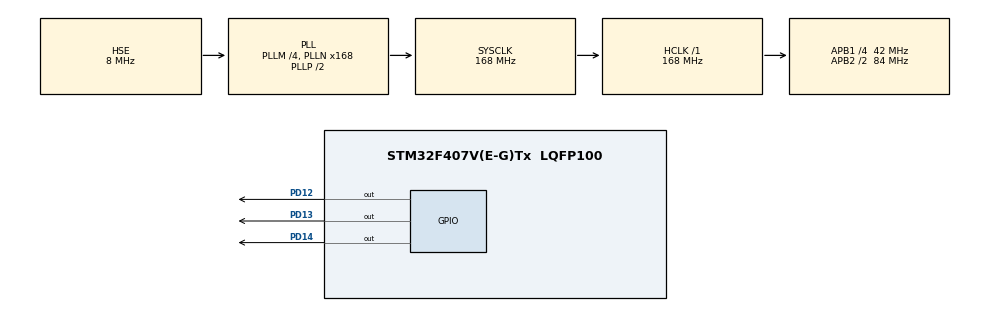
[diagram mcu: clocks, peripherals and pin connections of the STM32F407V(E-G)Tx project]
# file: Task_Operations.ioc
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FREERTOS.BinarySemaphores01=binSema
FREERTOS.INCLUDE_vTaskDelayUntil=1
FREERTOS.Tasks01=myTask01,2,128,init_task_01,Default;myTask02,1,128,init_task_02,Default;myTask03,0,128,init_task_03,Default
Mcu.Family=STM32F4
Mcu.Name=STM32F407V(E-G)Tx
Mcu.Package=LQFP100
NVIC.PriorityGroup=NVIC_PRIORITYGROUP_4
NVIC.TIM1_UP_TIM10_IRQn=true\:0\:0\:false\:false\:true
NVIC.TimeBase=TIM1_UP_TIM10_IRQn
NVIC.TimeBaseIP=TIM1
PA13.Mode=Serial-Wire
PA13.Signal=SYS_JTMS-SWDIO
PA14.Mode=Serial-Wire
PA14.Signal=SYS_JTCK-SWCLK
PD12.GPIO_ModeDefaultOutputPP=GPIO_MODE_OUTPUT_PP
PD12.GPIO_PuPd=GPIO_NOPULL
PD12.GPIO_Speed=GPIO_SPEED_FREQ_VERY_HIGH
PD12.PinState=GPIO_PIN_SET
PD12.Signal=GPIO_Output
PD13.GPIO_ModeDefaultOutputPP=GPIO_MODE_OUTPUT_PP
PD13.GPIO_PuPd=GPIO_NOPULL
PD13.GPIO_Speed=GPIO_SPEED_FREQ_VERY_HIGH
PD13.PinState=GPIO_PIN_SET
PD13.Signal=GPIO_Output
PD14.GPIO_ModeDefaultOutputPP=GPIO_MODE_OUTPUT_PP
PD14.GPIO_PuPd=GPIO_NOPULL
PD14.GPIO_Speed=GPIO_SPEED_FREQ_VERY_HIGH
PD14.PinState=GPIO_PIN_SET
PD14.Signal=GPIO_Output
PH0-OSC_IN.Mode=HSE-External-Oscillator
PH0-OSC_IN.Signal=RCC_OSC_IN
PH1-OSC_OUT.Mode=HSE-External-Oscillator
PH1-OSC_OUT.Signal=RCC_OSC_OUT
ProjectManager.HeapSize=0x600
ProjectManager.StackSize=0x400
ProjectManager.TargetToolchain=MDK-ARM V5
RCC.48MHZClocksFreq_Value=84000000
RCC.AHBFreq_Value=168000000
RCC.APB1CLKDivider=RCC_HCLK_DIV4
RCC.APB1Freq_Value=42000000
RCC.APB1TimCLKDivider=1
RCC.APB1TimFreq_Value=42000000
RCC.APB2CLKDivider=RCC_HCLK_DIV2
RCC.APB2Freq_Value=84000000
RCC.APB2TimCLKDivider=1
RCC.APB2TimFreq_Value=84000000
RCC.CortexFreq_Value=168000000
RCC.HCLKFreq_Value=168000000
RCC.HSE_VALUE=8000000
RCC.HSI_VALUE=16000000
RCC.LSE_VALUE=32768
RCC.PLLM=4
RCC.PLLN=168
RCC.PLLSourceVirtual=RCC_PLLSOURCE_HSE
RCC.SYSCLKFreq_VALUE=168000000
RCC.SYSCLKSource=RCC_SYSCLKSOURCE_PLLCLK
RCC.VCOOutputFreq_Value=336000000
VP_FREERTOS_VS_ENABLE.Mode=Enabled
VP_SYS_VS_tim1.Mode=TIM1
board=Task_Operations

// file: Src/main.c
/**
  ******************************************************************************
  * File Name          : main.c
  * Description        : Main program body
  ******************************************************************************
  *
  * COPYRIGHT(c) 2021 STMicroelectronics
  *
  * Redistribution and use in source and binary forms, with or without modification,
  * are permitted provided that the following conditions are met:
  *   1. Redistributions of source code must retain the above copyright notice,
  *      this list of conditions and the following disclaimer.
  *   2. Redistributions in binary form must reproduce the above copyright notice,
  *      this list of conditions and the following disclaimer in the documentation
  *      and/or other materials provided with the distribution.
  *   3. Neither the name of STMicroelectronics nor the names of its contributors
  *      may be used to endorse or promote products derived from this software
  *      without specific prior written permission.
  *
  * THIS SOFTWARE IS PROVIDED BY THE COPYRIGHT HOLDERS AND CONTRIBUTORS "AS IS"
  * AND ANY EXPRESS OR IMPLIED WARRANTIES, INCLUDING, BUT NOT LIMITED TO, THE
  * IMPLIED WARRANTIES OF MERCHANTABILITY AND FITNESS FOR A PARTICULAR PURPOSE ARE
  * DISCLAIMED. IN NO EVENT SHALL THE COPYRIGHT HOLDER OR CONTRIBUTORS BE LIABLE
  * FOR ANY DIRECT, INDIRECT, INCIDENTAL, SPECIAL, EXEMPLARY, OR CONSEQUENTIAL
  * DAMAGES (INCLUDING, BUT NOT LIMITED TO, PROCUREMENT OF SUBSTITUTE GOODS OR
  * SERVICES; LOSS OF USE, DATA, OR PROFITS; OR BUSINESS INTERRUPTION) HOWEVER
  * CAUSED AND ON ANY THEORY OF LIABILITY, WHETHER IN CONTRACT, STRICT LIABILITY,
  * OR TORT (INCLUDING NEGLIGENCE OR OTHERWISE) ARISING IN ANY WAY OUT OF THE USE
  * OF THIS SOFTWARE, EVEN IF ADVISED OF THE POSSIBILITY OF SUCH DAMAGE.
  *
  ******************************************************************************
  */
#include "stm32f4xx_hal.h"
#include "cmsis_os.h"

osThreadId myTask01Handle;
osThreadId myTask02Handle;
osThreadId myTask03Handle;
osSemaphoreId binSemaHandle;

/* USER CODE BEGIN PV */
/* Private variables ---------------------------------------------------------*/

/* USER CODE END PV */

void SystemClock_Config(void);
static void MX_GPIO_Init(void);
void init_task_01(void const * argument);
void init_task_02(void const * argument);
void init_task_03(void const * argument);

/* USER CODE BEGIN PFP */
/* Private function prototypes -----------------------------------------------*/

/* USER CODE END PFP */

int main(void)
{

  /* MCU Configuration----------------------------------------------------------*/

  /* Reset of all peripherals, Initializes the Flash interface and the Systick. */
  HAL_Init();

  /* Configure the system clock */
  SystemClock_Config();

  /* Initialize all configured peripherals */
  MX_GPIO_Init();

  /* Create the semaphores(s) */
  /* definition and creation of binSema */
  osSemaphoreDef(binSema);
  binSemaHandle = osSemaphoreCreate(osSemaphore(binSema), 1);

  /* Create the thread(s) */
  /* definition and creation of myTask01 */
  osThreadDef(myTask01, init_task_01, osPriorityHigh, 0, 128);
  myTask01Handle = osThreadCreate(osThread(myTask01), NULL);

  /* definition and creation of myTask02 */
  osThreadDef(myTask02, init_task_02, osPriorityAboveNormal, 0, 128);
  myTask02Handle = osThreadCreate(osThread(myTask02), NULL);

  /* definition and creation of myTask03 */
  osThreadDef(myTask03, init_task_03, osPriorityNormal, 0, 128);
  myTask03Handle = osThreadCreate(osThread(myTask03), NULL);

  /* USER CODE BEGIN RTOS_QUEUES */
  /* add queues, ... */
	printf("START\n");
  /* USER CODE END RTOS_QUEUES */

  /* Start scheduler */
  osKernelStart();

  /* We should never get here as control is now taken by the scheduler */

  /* Infinite loop */
  while (1)
  {

  }

}

/** System Clock Configuration
*/
void SystemClock_Config(void)
{

  RCC_OscInitTypeDef RCC_OscInitStruct;
  RCC_ClkInitTypeDef RCC_ClkInitStruct;

  __HAL_RCC_PWR_CLK_ENABLE();

  __HAL_PWR_VOLTAGESCALING_CONFIG(PWR_REGULATOR_VOLTAGE_SCALE1);

  RCC_OscInitStruct.OscillatorType = RCC_OSCILLATORTYPE_HSE;
  RCC_OscInitStruct.HSEState = RCC_HSE_ON;
  RCC_OscInitStruct.PLL.PLLState = RCC_PLL_ON;
  RCC_OscInitStruct.PLL.PLLSource = RCC_PLLSOURCE_HSE;
  RCC_OscInitStruct.PLL.PLLM = 4;
  RCC_OscInitStruct.PLL.PLLN = 168;
  RCC_OscInitStruct.PLL.PLLP = RCC_PLLP_DIV2;
  RCC_OscInitStruct.PLL.PLLQ = 4;
  HAL_RCC_OscConfig(&RCC_OscInitStruct);

  RCC_ClkInitStruct.ClockType = RCC_CLOCKTYPE_HCLK|RCC_CLOCKTYPE_SYSCLK
                              |RCC_CLOCKTYPE_PCLK1|RCC_CLOCKTYPE_PCLK2;
  RCC_ClkInitStruct.SYSCLKSource = RCC_SYSCLKSOURCE_PLLCLK;
  RCC_ClkInitStruct.AHBCLKDivider = RCC_SYSCLK_DIV1;
  RCC_ClkInitStruct.APB1CLKDivider = RCC_HCLK_DIV4;
  RCC_ClkInitStruct.APB2CLKDivider = RCC_HCLK_DIV2;
  HAL_RCC_ClockConfig(&RCC_ClkInitStruct, FLASH_LATENCY_5);

  HAL_SYSTICK_Config(HAL_RCC_GetHCLKFreq()/1000);

  HAL_SYSTICK_CLKSourceConfig(SYSTICK_CLKSOURCE_HCLK);

  /* SysTick_IRQn interrupt configuration */
  HAL_NVIC_SetPriority(SysTick_IRQn, 15, 0);
}

/** Configure pins as
        * Analog
        * Input
        * Output
        * EVENT_OUT
        * EXTI
*/
void MX_GPIO_Init(void)
{

  GPIO_InitTypeDef GPIO_InitStruct;

  /* GPIO Ports Clock Enable */
  __HAL_RCC_GPIOH_CLK_ENABLE();
  __HAL_RCC_GPIOD_CLK_ENABLE();
  __HAL_RCC_GPIOA_CLK_ENABLE();

  /*Configure GPIO pin Output Level */
  HAL_GPIO_WritePin(GPIOD, GPIO_PIN_12|GPIO_PIN_13|GPIO_PIN_14, GPIO_PIN_SET);

  /*Configure GPIO pins : PD12 PD13 PD14 */
  GPIO_InitStruct.Pin = GPIO_PIN_12|GPIO_PIN_13|GPIO_PIN_14;
  GPIO_InitStruct.Mode = GPIO_MODE_OUTPUT_PP;
  GPIO_InitStruct.Pull = GPIO_NOPULL;
  GPIO_InitStruct.Speed = GPIO_SPEED_FREQ_VERY_HIGH;
  HAL_GPIO_Init(GPIOD, &GPIO_InitStruct);

}

/* init_task_01 function */
void init_task_01(void const * argument)
{

  /* USER CODE BEGIN 5 */
	uint8_t index1 = 0;
  /* Infinite loop */
  for(;;)
  {
		printf("task 1 = %d\n", index1++);
    osDelay(1000);
  }
  /* USER CODE END 5 */
}

/* init_task_02 function */
void init_task_02(void const * argument)
{
  /* USER CODE BEGIN init_task_02 */
	uint8_t index2 = 0;
  /* Infinite loop */
  for(;;)
  {
		printf("task 2 = %d\n", index2++);
		if(index2 == 3)
		{
			printf("task 1 suppend\n");
			osThreadSuspend(myTask01Handle);
		}
		if(index2 == 6)
		{
			printf("task2 delay until\n");
			uint32_t PreviousWakeTime = osKernelSysTick();
		  osDelayUntil(&PreviousWakeTime, 4000);
		}
		if(index2 == 8)
		{
			printf("task2 take binSema\n");
			osSemaphoreWait(binSemaHandle, osWaitForever);
		}
		if(index2 == 16)
		{
			printf("task 2 give binSema\n");
			osSemaphoreRelease(binSemaHandle);
		}
		osDelay(1000);
  }
  /* USER CODE END init_task_02 */
}

/* init_task_03 function */
void init_task_03(void const * argument)
{
  /* USER CODE BEGIN init_task_03 */
	uint8_t index3 = 0;
  /* Infinite loop */
  for(;;)
  {
		printf("task3 = %d\n", index3++);
		if(index3 == 8)
		{
			printf("task1 resume\n");
			osThreadResume(myTask01Handle);
		}
		if(index3 == 14)
		{
			printf("task3 take binSema\n");
			osSemaphoreWait(binSemaHandle, osWaitForever);
		}
		osDelay(1000);
  }
  /* USER CODE END init_task_03 */
}

/************************ (C) COPYRIGHT STMicroelectronics *****END OF FILE****/
